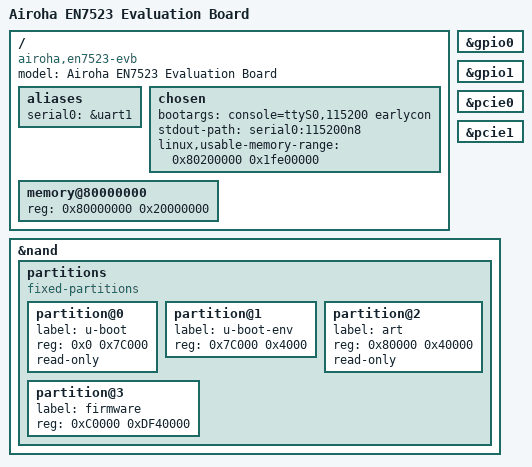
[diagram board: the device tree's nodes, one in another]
// SPDX-License-Identifier: (GPL-2.0-only OR BSD-2-Clause)
/dts-v1/;

/* Bootloader installs ATF here */
/memreserve/ 0x80000000 0x200000;

#include "en7523.dtsi"

/ {
	model = "Airoha EN7523 Evaluation Board";
	compatible = "airoha,en7523-evb", "airoha,en7523";

	aliases {
		serial0 = &uart1;
	};

	chosen {
		bootargs = "console=ttyS0,115200 earlycon";
		stdout-path = "serial0:115200n8";
		linux,usable-memory-range = <0x80200000 0x1fe00000>;
	};

	memory@80000000 {
		device_type = "memory";
		reg = <0x80000000 0x20000000>;
	};
};

&gpio0 {
	status = "okay";
};

&gpio1 {
	status = "okay";
};

&pcie0 {
	status = "okay";
};

&pcie1 {
	status = "okay";
};

&nand {
	partitions {
		compatible = "fixed-partitions";
		#address-cells = <1>;
		#size-cells = <1>;

		partition@0 {
			label = "u-boot";
			reg = <0x0 0x7C000>;
			read-only;
		};

		partition@1 {
			label = "u-boot-env";
			reg = <0x7C000 0x4000>;
		};

		partition@2 {
			label = "art";
			reg = <0x80000 0x40000>;
			read-only;
		};

		partition@3 {
			label = "firmware";
			reg = <0xC0000 0xDF40000>;
		};
	};
};
